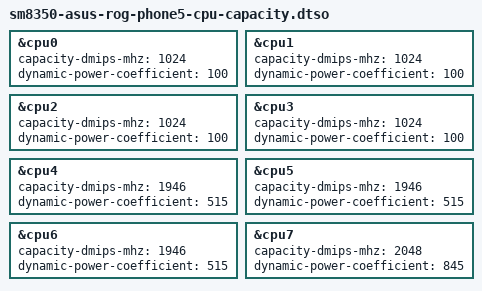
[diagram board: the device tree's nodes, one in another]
// SPDX-License-Identifier: BSD-3-Clause
/dts-v1/;
/plugin/;

/*
 * Heterogeneous CPU capacity and energy data, absent from sm8350.dtsi: without
 * them every core reports capacity 1024 and the scheduler treats the 1.8 GHz
 * A55s like the 2.84 GHz X1. Values from the stock lahaina.dtsi (1024/100,
 * 1946/515, 2048/845); with frequency scaling the capacities come out near
 * 324 / 828 / 1024. Compose feature cpucap.
 *
 * On r25 capacity-aware placement moved Denial's raster and UI threads to the
 * A55s (quick settings 5 -> 60 dropped frames, keyboard 7 -> 77; 50 / 33 with
 * sched_energy_aware=0). With it, the graphical session gets a cpu.uclamp.min
 * boost so its threads stay on the big cores.
 */
&cpu0 {
	capacity-dmips-mhz = <1024>;
	dynamic-power-coefficient = <100>;
};

&cpu1 {
	capacity-dmips-mhz = <1024>;
	dynamic-power-coefficient = <100>;
};

&cpu2 {
	capacity-dmips-mhz = <1024>;
	dynamic-power-coefficient = <100>;
};

&cpu3 {
	capacity-dmips-mhz = <1024>;
	dynamic-power-coefficient = <100>;
};

&cpu4 {
	capacity-dmips-mhz = <1946>;
	dynamic-power-coefficient = <515>;
};

&cpu5 {
	capacity-dmips-mhz = <1946>;
	dynamic-power-coefficient = <515>;
};

&cpu6 {
	capacity-dmips-mhz = <1946>;
	dynamic-power-coefficient = <515>;
};

&cpu7 {
	capacity-dmips-mhz = <2048>;
	dynamic-power-coefficient = <845>;
};
